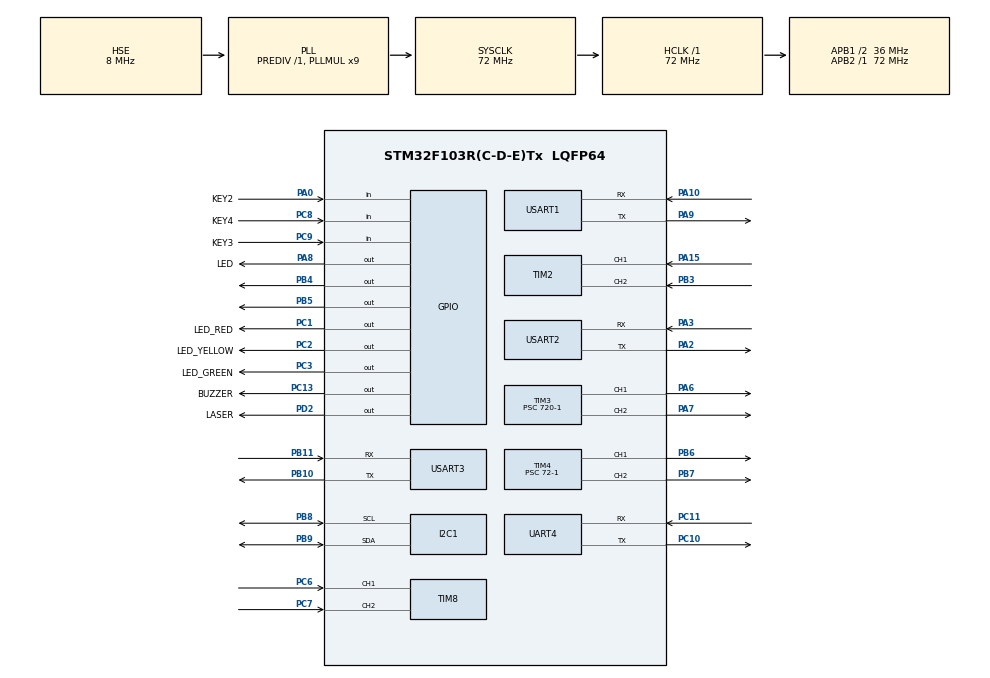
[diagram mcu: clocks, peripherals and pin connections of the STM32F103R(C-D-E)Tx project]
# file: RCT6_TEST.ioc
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Dma.Request0=USART1_RX
Dma.USART1_RX.0.Direction=DMA_PERIPH_TO_MEMORY
Dma.USART1_RX.0.Instance=DMA1_Channel5
Dma.USART1_RX.0.MemDataAlignment=DMA_MDATAALIGN_BYTE
Dma.USART1_RX.0.MemInc=DMA_MINC_ENABLE
Dma.USART1_RX.0.Mode=DMA_NORMAL
Dma.USART1_RX.0.PeriphDataAlignment=DMA_PDATAALIGN_BYTE
Dma.USART1_RX.0.PeriphInc=DMA_PINC_DISABLE
Dma.USART1_RX.0.Priority=DMA_PRIORITY_LOW
Mcu.Family=STM32F1
Mcu.Name=STM32F103R(C-D-E)Tx
Mcu.Package=LQFP64
NVIC.DMA1_Channel5_IRQn=true\:0\:0\:false\:false\:true\:false\:true\:true
NVIC.PriorityGroup=NVIC_PRIORITYGROUP_4
NVIC.TIM5_IRQn=true\:0\:0\:false\:false\:true\:true\:true\:true
NVIC.TIM6_IRQn=true\:0\:0\:false\:false\:true\:true\:true\:true
NVIC.TIM7_IRQn=true\:0\:0\:false\:false\:true\:true\:true\:true
NVIC.UART4_IRQn=true\:0\:0\:false\:false\:true\:true\:true\:true
NVIC.USART1_IRQn=true\:0\:0\:false\:false\:true\:true\:true\:true
NVIC.USART2_IRQn=true\:0\:0\:false\:false\:true\:true\:true\:true
NVIC.USART3_IRQn=true\:0\:0\:false\:false\:true\:true\:true\:true
PA0-WKUP.GPIO_Label=KEY2
PA0-WKUP.Signal=GPIO_Input
PA10.Mode=Asynchronous
PA10.Signal=USART1_RX
PA13.Mode=Serial_Wire
PA13.Signal=SYS_JTMS-SWDIO
PA14.Mode=Serial_Wire
PA14.Signal=SYS_JTCK-SWCLK
PA15.Signal=S_TIM2_CH1_ETR
PA2.Mode=Asynchronous
PA2.Signal=USART2_TX
PA3.Mode=Asynchronous
PA3.Signal=USART2_RX
PA6.Signal=S_TIM3_CH1
PA7.Signal=S_TIM3_CH2
PA8.GPIO_Label=LED
PA8.Signal=GPIO_Output
PA9.Mode=Asynchronous
PA9.Signal=USART1_TX
PB10.Mode=Asynchronous
PB10.Signal=USART3_TX
PB11.Mode=Asynchronous
PB11.Signal=USART3_RX
PB3.Signal=S_TIM2_CH2
PB4.Signal=GPIO_Output
PB5.Signal=GPIO_Output
PB6.Signal=S_TIM4_CH1
PB7.Signal=S_TIM4_CH2
PB8.Mode=I2C
PB8.Signal=I2C1_SCL
PB9.Mode=I2C
PB9.Signal=I2C1_SDA
PC1.GPIO_Label=LED_RED
PC1.Signal=GPIO_Output
PC10.Mode=Asynchronous
PC10.Signal=UART4_TX
PC11.Mode=Asynchronous
PC11.Signal=UART4_RX
PC13-TAMPER-RTC.GPIO_Label=BUZZER
PC13-TAMPER-RTC.Signal=GPIO_Output
PC2.GPIO_Label=LED_YELLOW
PC2.Signal=GPIO_Output
PC3.GPIO_Label=LED_GREEN
PC3.Signal=GPIO_Output
PC6.Signal=S_TIM8_CH1
PC7.Signal=S_TIM8_CH2
PC8.GPIO_Label=KEY4
PC8.Signal=GPIO_Input
PC9.GPIO_Label=KEY3
PC9.Signal=GPIO_Input
PD0-OSC_IN.Mode=HSE-External-Oscillator
PD0-OSC_IN.Signal=RCC_OSC_IN
PD1-OSC_OUT.Mode=HSE-External-Oscillator
PD1-OSC_OUT.Signal=RCC_OSC_OUT
PD2.GPIO_Label=LASER
PD2.Signal=GPIO_Output
ProjectManager.HeapSize=0x200
ProjectManager.StackSize=0x400
ProjectManager.TargetToolchain=MDK-ARM V5.32
RCC.AHBFreq_Value=72000000
RCC.APB1CLKDivider=RCC_HCLK_DIV2
RCC.APB1Freq_Value=36000000
RCC.APB1TimFreq_Value=72000000
RCC.APB2Freq_Value=72000000
RCC.APB2TimFreq_Value=72000000
RCC.HCLKFreq_Value=72000000
RCC.PLLMUL=RCC_PLL_MUL9
RCC.PLLSourceVirtual=RCC_PLLSOURCE_HSE
RCC.SYSCLKFreq_VALUE=72000000
RCC.SYSCLKSource=RCC_SYSCLKSOURCE_PLLCLK
RCC.USBFreq_Value=72000000
SH.S_TIM2_CH1_ETR.0=TIM2_CH1,Encoder_Interface
SH.S_TIM2_CH2.0=TIM2_CH2,Encoder_Interface
SH.S_TIM3_CH1.0=TIM3_CH1,PWM Generation1 CH1
SH.S_TIM3_CH2.0=TIM3_CH2,PWM Generation2 CH2
SH.S_TIM4_CH1.0=TIM4_CH1,PWM Generation1 CH1
SH.S_TIM4_CH2.0=TIM4_CH2,PWM Generation2 CH2
SH.S_TIM8_CH1.0=TIM8_CH1,Encoder_Interface
SH.S_TIM8_CH2.0=TIM8_CH2,Encoder_Interface
TIM3.Channel-PWM\ Generation1\ CH1=TIM_CHANNEL_1
TIM3.Channel-PWM\ Generation2\ CH2=TIM_CHANNEL_2
TIM3.Period=2000-1
TIM3.Prescaler=720-1
TIM4.Channel-PWM\ Generation1\ CH1=TIM_CHANNEL_1
TIM4.Channel-PWM\ Generation2\ CH2=TIM_CHANNEL_2
TIM4.Period=1000-1
TIM4.Prescaler=72-1
TIM5.Period=1000-1
TIM5.Prescaler=72-1
TIM6.Period=10000-1
TIM6.Prescaler=72-1
TIM7.Period=20000-1
TIM7.Prescaler=72-1
UART4.VirtualMode=Asynchronous
USART1.VirtualMode=VM_ASYNC
USART2.VirtualMode=VM_ASYNC
USART3.VirtualMode=VM_ASYNC
VP_TIM1_VS_ClockSourceINT.Mode=Internal
VP_TIM3_VS_ClockSourceINT.Mode=Internal
VP_TIM4_VS_ClockSourceINT.Mode=Internal
VP_TIM5_VS_ClockSourceINT.Mode=Internal
VP_TIM6_VS_ClockSourceINT.Mode=Enable_Timer
VP_TIM7_VS_ClockSourceINT.Mode=Enable_Timer
board=custom

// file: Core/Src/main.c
/* USER CODE BEGIN Header */
/**
  ******************************************************************************
  * @file           : main.c
  * @brief          : Main program body
  ******************************************************************************
  * @attention
  *
  * Copyright (c) 2023 STMicroelectronics.
  * All rights reserved.
  *
  * This software is licensed under terms that can be found in the LICENSE file
  * in the root directory of this software component.
  * If no LICENSE file comes with this software, it is provided AS-IS.
  *
  ******************************************************************************
  */
/* USER CODE END Header */
#include "main.h"
#include "dma.h"
#include "i2c.h"
#include "tim.h"
#include "usart.h"
#include "gpio.h"

void SystemClock_Config(void);

int main(void)
{

  /* MCU Configuration--------------------------------------------------------*/

  /* Reset of all peripherals, Initializes the Flash interface and the Systick. */
  HAL_Init();

  /* Configure the system clock */
  SystemClock_Config();

  /* Initialize all configured peripherals */
  MX_GPIO_Init();
  MX_DMA_Init();
  MX_TIM1_Init();
  MX_TIM2_Init();
  MX_TIM3_Init();
  MX_TIM4_Init();
  MX_TIM5_Init();
  MX_TIM6_Init();
  MX_TIM7_Init();
  MX_TIM8_Init();
  MX_UART4_Init();
  MX_USART1_UART_Init();
  MX_USART2_UART_Init();
  MX_USART3_UART_Init();
  MX_I2C1_Init();
  /* USER CODE BEGIN 2 */
   HAL_TIM_PWM_Start(&htim3,TIM_CHANNEL_1); //pwm通道初始化 用于控制舵机
	 HAL_TIM_PWM_Start(&htim3,TIM_CHANNEL_2); //pwm通道初始化 用于控制舵机
	 HAL_TIM_PWM_Start(&htim4,TIM_CHANNEL_1); //pwm通道初始化 用于控制舵机
	 HAL_TIM_PWM_Start(&htim4,TIM_CHANNEL_2); //pwm通道初始化 用于控制舵机
	 HAL_TIM_Base_Start_IT(&htim5);      //1000HZ     //定时器开始工作
	 HAL_TIM_Base_Start_IT(&htim6);    //100HZ
	 HAL_TIM_Base_Start_IT(&htim7);   //50HZ
	 HAL_TIM_Encoder_Start(&htim8,TIM_CHANNEL_1 | TIM_CHANNEL_2);//开启编码器
	 HAL_TIM_Encoder_Start(&htim2,TIM_CHANNEL_1 | TIM_CHANNEL_2);//开启编码器
	 init_actuator();

  /* USER CODE END 2 */

  /* Infinite loop */
  while (1)
  {

    /* USER CODE BEGIN 3 */

		//test1();

  }
  /* USER CODE END 3 */
}

void SystemClock_Config(void)
{
  RCC_OscInitTypeDef RCC_OscInitStruct = {0};
  RCC_ClkInitTypeDef RCC_ClkInitStruct = {0};

  /** Initializes the RCC Oscillators according to the specified parameters
  * in the RCC_OscInitTypeDef structure.
  */
  RCC_OscInitStruct.OscillatorType = RCC_OSCILLATORTYPE_HSE;
  RCC_OscInitStruct.HSEState = RCC_HSE_ON;
  RCC_OscInitStruct.HSEPredivValue = RCC_HSE_PREDIV_DIV1;
  RCC_OscInitStruct.HSIState = RCC_HSI_ON;
  RCC_OscInitStruct.PLL.PLLState = RCC_PLL_ON;
  RCC_OscInitStruct.PLL.PLLSource = RCC_PLLSOURCE_HSE;
  RCC_OscInitStruct.PLL.PLLMUL = RCC_PLL_MUL9;
  if (HAL_RCC_OscConfig(&RCC_OscInitStruct) != HAL_OK)
  {
    Error_Handler();
  }

  /** Initializes the CPU, AHB and APB buses clocks
  */
  RCC_ClkInitStruct.ClockType = RCC_CLOCKTYPE_HCLK|RCC_CLOCKTYPE_SYSCLK
                              |RCC_CLOCKTYPE_PCLK1|RCC_CLOCKTYPE_PCLK2;
  RCC_ClkInitStruct.SYSCLKSource = RCC_SYSCLKSOURCE_PLLCLK;
  RCC_ClkInitStruct.AHBCLKDivider = RCC_SYSCLK_DIV1;
  RCC_ClkInitStruct.APB1CLKDivider = RCC_HCLK_DIV2;
  RCC_ClkInitStruct.APB2CLKDivider = RCC_HCLK_DIV1;

  if (HAL_RCC_ClockConfig(&RCC_ClkInitStruct, FLASH_LATENCY_2) != HAL_OK)
  {
    Error_Handler();
  }
}

void Error_Handler(void)
{
  __disable_irq();
  while (1)
  {
  }
}
